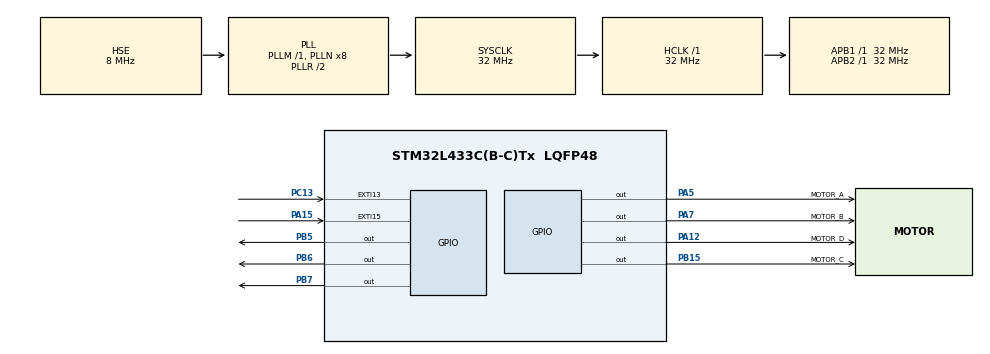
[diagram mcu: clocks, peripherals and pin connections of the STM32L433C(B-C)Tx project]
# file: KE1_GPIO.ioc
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Mcu.Family=STM32L4
RCC.MSI_VALUE=4000000
RCC.PLLSourceVirtual=RCC_PLLSOURCE_HSE
RCC.CortexFreq_Value=32000000
PH0-OSC_IN\ (PH0).Signal=RCC_OSC_IN
PC13.Signal=GPXTI13
PA15\ (JTDI).Signal=GPXTI15
PB15.Signal=GPIO_Output
PA12.GPIO_Label=MOTOR_D
PH1-OSC_OUT\ (PH1).Signal=RCC_OSC_OUT
RCC.SYSCLKSource=RCC_SYSCLKSOURCE_PLLCLK
ProjectManager.StackSize=0x400
PA12.Signal=GPIO_Output
ProjectManager.TargetToolchain=STM32CubeIDE
RCC.HCLKFreq_Value=32000000
RCC.APB2TimFreq_Value=32000000
PB6.Signal=GPIO_Output
PB5.PinState=GPIO_PIN_SET
RCC.USBFreq_Value=32000000
RCC.LSE_VALUE=32768
RCC.AHBFreq_Value=32000000
NVIC.EXTI15_10_IRQn=true\:4\:0\:true\:false\:true\:true\:true
PA5.Signal=GPIO_Output
PH1-OSC_OUT\ (PH1).Mode=HSE-External-Oscillator
RCC.HSE_VALUE=8000000
board=custom
RCC.VCOOutputFreq_Value=64000000
RCC.APB2Freq_Value=32000000
PB15.GPIO_Label=MOTOR_C
RCC.ADCFreq_Value=32000000
PC13.GPIO_PuPd=GPIO_PULLUP
PA15\ (JTDI).GPIO_PuPd=GPIO_PULLUP
PB7.Signal=GPIO_Output
Mcu.Name=STM32L433C(B-C)Tx
PB7.PinState=GPIO_PIN_SET
RCC.SYSCLKFreq_VALUE=32000000
Mcu.Package=LQFP48
PB5.Signal=GPIO_Output
PA7.GPIO_Label=MOTOR_B
PA5.GPIO_Label=MOTOR_A
PB6.PinState=GPIO_PIN_SET
ProjectManager.HeapSize=0x200
RCC.HSI_VALUE=16000000
NVIC.PriorityGroup=NVIC_PRIORITYGROUP_4
RCC.APB1TimFreq_Value=32000000
RCC.APB1Freq_Value=32000000
PH0-OSC_IN\ (PH0).Mode=HSE-External-Oscillator
RCC.HSI48_VALUE=48000000
PA7.Signal=GPIO_Output

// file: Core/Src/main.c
/* USER CODE BEGIN Header */
/**
  ******************************************************************************
  * @file           : main.c
  * @brief          : Main program body
  ******************************************************************************
  * @attention
  *
  * <h2><center>&copy; Copyright (c) 2021 STMicroelectronics.
  * All rights reserved.</center></h2>
  *
  * This software component is licensed by ST under BSD 3-Clause license,
  * the "License"; You may not use this file except in compliance with the
  * License. You may obtain a copy of the License at:
  *                        opensource.org/licenses/BSD-3-Clause
  *
  ******************************************************************************
  */
/* USER CODE END Header */
#include "main.h"
#include "gpio.h"

void SystemClock_Config(void);

int main(void)
{

  /* MCU Configuration--------------------------------------------------------*/

  /* Reset of all peripherals, Initializes the Flash interface and the Systick. */
  HAL_Init();

  /* Configure the system clock */
  SystemClock_Config();

  /* Initialize all configured peripherals */
  MX_GPIO_Init();
  /* USER CODE BEGIN 2 */

  Step_Motor_Start(90, 0);//正转360
  Step_Motor_Stop();

  /* USER CODE END 2 */

  /* Infinite loop */
  while (1)
  {

  }
}

void SystemClock_Config(void)
{
  RCC_OscInitTypeDef RCC_OscInitStruct = {0};
  RCC_ClkInitTypeDef RCC_ClkInitStruct = {0};

  /** Initializes the RCC Oscillators according to the specified parameters
  * in the RCC_OscInitTypeDef structure.
  */
  RCC_OscInitStruct.OscillatorType = RCC_OSCILLATORTYPE_HSE;
  RCC_OscInitStruct.HSEState = RCC_HSE_ON;
  RCC_OscInitStruct.PLL.PLLState = RCC_PLL_ON;
  RCC_OscInitStruct.PLL.PLLSource = RCC_PLLSOURCE_HSE;
  RCC_OscInitStruct.PLL.PLLM = 1;
  RCC_OscInitStruct.PLL.PLLN = 8;
  RCC_OscInitStruct.PLL.PLLP = RCC_PLLP_DIV7;
  RCC_OscInitStruct.PLL.PLLQ = RCC_PLLQ_DIV2;
  RCC_OscInitStruct.PLL.PLLR = RCC_PLLR_DIV2;
  if (HAL_RCC_OscConfig(&RCC_OscInitStruct) != HAL_OK)
  {
    Error_Handler();
  }
  /** Initializes the CPU, AHB and APB buses clocks
  */
  RCC_ClkInitStruct.ClockType = RCC_CLOCKTYPE_HCLK|RCC_CLOCKTYPE_SYSCLK
                              |RCC_CLOCKTYPE_PCLK1|RCC_CLOCKTYPE_PCLK2;
  RCC_ClkInitStruct.SYSCLKSource = RCC_SYSCLKSOURCE_PLLCLK;
  RCC_ClkInitStruct.AHBCLKDivider = RCC_SYSCLK_DIV1;
  RCC_ClkInitStruct.APB1CLKDivider = RCC_HCLK_DIV1;
  RCC_ClkInitStruct.APB2CLKDivider = RCC_HCLK_DIV1;

  if (HAL_RCC_ClockConfig(&RCC_ClkInitStruct, FLASH_LATENCY_1) != HAL_OK)
  {
    Error_Handler();
  }
  /** Configure the main internal regulator output voltage
  */
  if (HAL_PWREx_ControlVoltageScaling(PWR_REGULATOR_VOLTAGE_SCALE1) != HAL_OK)
  {
    Error_Handler();
  }
}

void Error_Handler(void)
{
  __disable_irq();
  while (1)
  {
  }
}

/************************ (C) COPYRIGHT STMicroelectronics *****END OF FILE****/
